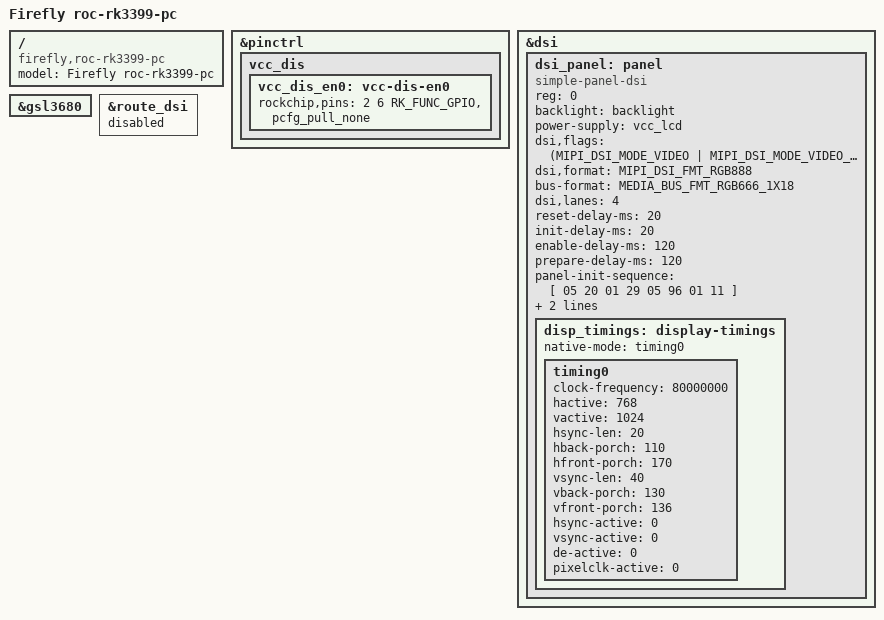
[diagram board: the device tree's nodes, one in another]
/dts-v1/;
#include "rk3399-roc-pc.dtsi"

/ {
	model = "Firefly roc-rk3399-pc";
	compatible = "firefly,roc-rk3399-pc", "rockchip,rk3399";

};

&pinctrl {
	vcc_dis {
		vcc_dis_en0: vcc-dis-en0 {
			rockchip,pins =
				<2 6 RK_FUNC_GPIO &pcfg_pull_none>;
		};
	};
};

//mipi
&dsi {	
	status = "okay";
	//status = "okay";
	dsi_panel: panel {
		compatible ="simple-panel-dsi";
		reg = <0>;
		backlight = <&backlight>;
		power-supply = <&vcc_lcd>;
		dsi,flags = <(MIPI_DSI_MODE_VIDEO | MIPI_DSI_MODE_VIDEO_BURST)>;
		dsi,format = <MIPI_DSI_FMT_RGB888>;
		bus-format = <MEDIA_BUS_FMT_RGB666_1X18>;
		dsi,lanes = <4>;
		reset-delay-ms = <20>;
		init-delay-ms = <20>;
		enable-delay-ms = <120>;
		prepare-delay-ms = <120>;
		status = "okay";

		panel-init-sequence = [
			05 20 01 29
			05 96 01 11
		];

		panel-exit-sequence = [
			05 05 01 28
			05 78 01 10
		];

		disp_timings: display-timings {
			native-mode = <&timing0>;

			timing0: timing0 {
				clock-frequency = <80000000>;
				hactive = <768>;
				vactive = <1024>;
				hsync-len = <20>;
				hback-porch = <110>;
				hfront-porch = <170>;
				vsync-len = <40>;
				vback-porch = <130>;
				vfront-porch = <136>;
				hsync-active = <0>;
				vsync-active = <0>;
				de-active = <0>;
				pixelclk-active = <0>;
			};
		};
	};	
};

//TF
&gsl3680 {
	status = "okay";
};

//boot logo for MIPI screen
&route_dsi {
	status = "disabled";
};
